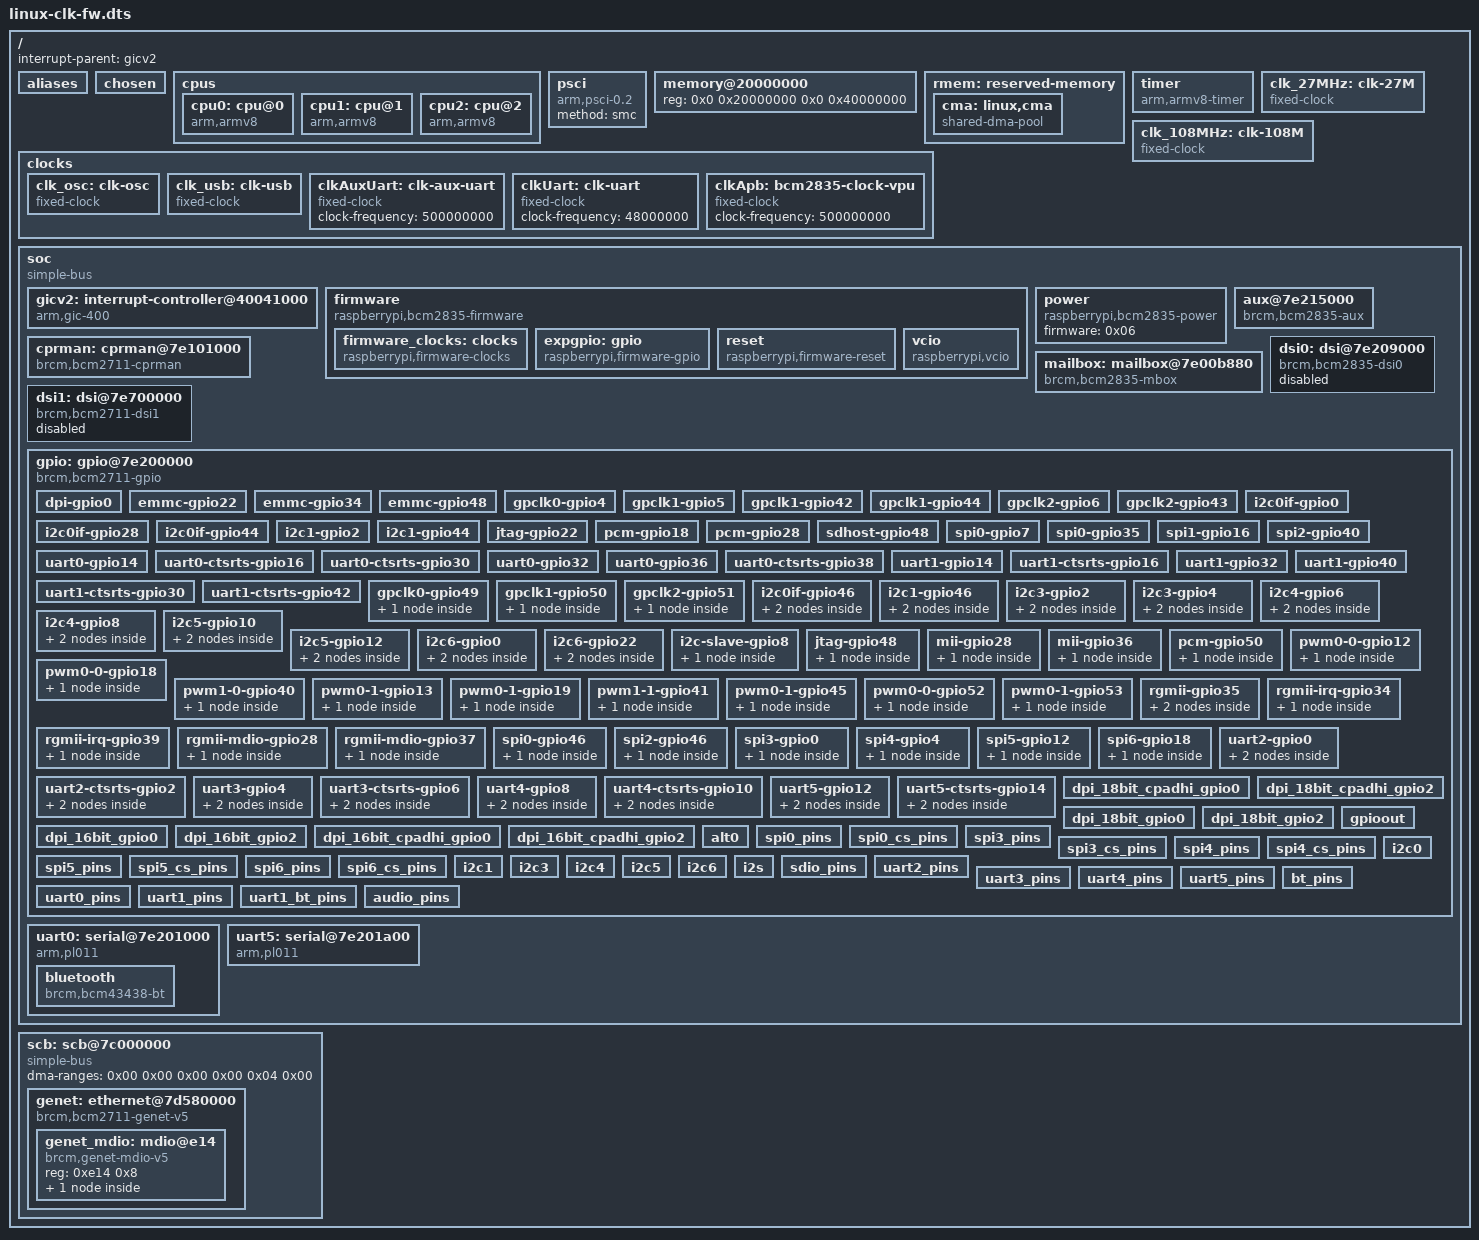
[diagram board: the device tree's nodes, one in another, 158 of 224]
/dts-v1/;

/ {
	#address-cells = <2>;
	#size-cells = <2>;
	interrupt-parent = <&gicv2>;


 aliases: aliases {
	  serial0 = &uart0;
	  serial5 = &uart5;
	  //serial1 = &uart1;
	  ethernet0 = &genet;
	  //clkosc = &clk_osc;
	  //clocks = <&cprman 0>;
	};

 chosen: chosen {
	  stdout-path = "serial0:115200n8";
	  bootargs = "earlycon console=serial0,115200 clk_ignore_unused ip=192.168.42.15 carrier_timeout=0";
	};


 cpus: cpus {
		#size-cells = <0x0>;
		#address-cells = <0x1>;

	cpu0: cpu@0 {
			compatible = "arm,armv8";
			device_type = "cpu";
			enable-method = "psci";
			reg = <0x0>;
		};

	cpu1:	cpu@1 {
			compatible = "arm,armv8";
			device_type = "cpu";
			enable-method = "psci";
			reg = <0x1>;
		};

	cpu2:	cpu@2 {
			compatible = "arm,armv8";
			device_type = "cpu";
			enable-method = "psci";
			reg = <0x2>;
		};

	};

	psci {
		compatible = "arm,psci-0.2";
		method = "smc";
	};

	memory@20000000 {
		reg = <0x0 0x20000000 0x0 0x40000000>;
		device_type = "memory";
	};

 rmem: reserved-memory {
		#address-cells = <0x02>;
		#size-cells = <0x01>;
		ranges;

	cma: linux,cma {
			compatible = "shared-dma-pool";
			size = <0x4000000>;
			reusable;
			linux,cma-default;
		};
	};

	timer {
		compatible = "arm,armv8-timer";
		interrupts = <0x1 0xd 0xf08 0x1 0xe 0xf08 0x1 0xb 0xf08 0x1 0xa 0xf08>;
	};

	clocks {

	clk_osc: clk-osc {
			clock-output-names = "osc";
			#clock-cells = <0x00>;
			clock-frequency = <0x337f980>;
			compatible = "fixed-clock";
			phandle = <0x03>;
		};

	clk_usb:	clk-usb {
			clock-output-names = "otg";
			#clock-cells = <0x00>;
			clock-frequency = <0x1c9c3800>;
			compatible = "fixed-clock";
			phandle = <0x16>;
		};

	    clkAuxUart: clk-aux-uart {
			compatible = "fixed-clock";
			#clock-cells = <0>;
			clock-frequency = <500000000>;
		};
	clkUart: clk-uart {
			compatible = "fixed-clock";
			#clock-cells = <0>;
			clock-frequency = <48000000>;
	  };

	clkApb: bcm2835-clock-vpu {
			compatible = "fixed-clock";
			#clock-cells = <0>;
			clock-frequency = <500000000>;
	  };


	};
 clk_27MHz: clk-27M {
		#clock-cells = <0x00>;
		compatible = "fixed-clock";
		clock-frequency = <0x19bfcc0>;
		clock-output-names = "27MHz-clock";
		phandle = <0x2f>;
	};

 clk_108MHz:	clk-108M {
		#clock-cells = <0x00>;
		compatible = "fixed-clock";
		clock-frequency = <0x66ff300>;
		clock-output-names = "108MHz-clock";
		phandle = <0x2a>;
	};


 soc: soc {
		compatible = "simple-bus";
		#address-cells = <0x01>;
		#size-cells = <0x01>;
		ranges = <0x7e000000 0x00 0xfe000000 0x1800000 0x7c000000 0x00 0xfc000000 0x2000000 0x40000000 0x00 0xff800000 0x800000>;
		dma-ranges = <0xc0000000 0x00 0x00 0x40000000 0x7c000000 0x00 0xfc000000 0x3800000>;
		phandle = <0x5f>;


	gicv2: interrupt-controller@40041000 {
			interrupts = <0x01 0x09 0xf04>;
			compatible = "arm,gic-400";
			#interrupt-cells = <0x03>;
			reg = <0x40041000 0x1000 0x40042000 0x2000 0x40044000 0x2000 0x40046000 0x2000>;
			phandle = <0x01>;
			interrupt-controller;
		};



	firmware:	firmware {
			compatible = "raspberrypi,bcm2835-firmware\0simple-mfd";
			#address-cells = <0x01>;
			#size-cells = <0x01>;
			mboxes = <&mailbox>;
			dma-ranges;
			phandle = <0x06>;

		firmware_clocks:	clocks {
				compatible = "raspberrypi,firmware-clocks";
				#clock-cells = <0x01>;
				phandle = <0x14>;
			};

		expgpio:	gpio {
				compatible = "raspberrypi,firmware-gpio";
				gpio-controller;
				#gpio-cells = <0x02>;
				status = "okay";
				gpio-line-names = "BT_ON\0WL_ON\0PWR_LED_OFF\0GLOBAL_RESET\0VDD_SD_IO_SEL\0CAM_GPIO\0SD_PWR_ON\0SD_OC_N";
				phandle = <0x0b>;
			};

		reset:	reset {
				compatible = "raspberrypi,firmware-reset";
				#reset-cells = <0x01>;
				phandle = <0x3f>;
			};

		vcio:	vcio {
				compatible = "raspberrypi,vcio";
				phandle = <0xdd>;
			};
		};
		
	power:	power {
			compatible = "raspberrypi,bcm2835-power";
			firmware = <0x06>;
			#power-domain-cells = <0x01>;
			phandle = <0x10>;
		};
		
		 aux@7e215000 {
		 	clocks = <&cprman 0x14>;
		 	#clock-cells = <0x01>;
		 	compatible = "brcm,bcm2835-aux";
		 	reg = <0x7e215000 0x08>;
		 	phandle = <0x11>;
		 };
		 
		 
	cprman: cprman@7e101000 {
		 	clocks = <&clk_osc &dsi0 0x00 &dsi0 0x01 &dsi0 0x02 &dsi1 0x00 &dsi1 0x01 &dsi1 0x02>;
		 	#clock-cells = <0x01>;
		 	compatible = "brcm,bcm2711-cprman";
		 	firmware = <0x06>;
		 	reg = <0x7e101000 0x2000>;
		 	phandle = <0x08>;
		 };


	mailbox:	mailbox@7e00b880 {
			compatible = "brcm,bcm2835-mbox";
			reg = <0x7e00b880 0x40>;
			interrupts = <0x00 0x21 0x04>;
			#mbox-cells = <0x00>;
			phandle = <0x35>;
		};

		 
		 
	dsi0:	 dsi@7e209000 {
		 	power-domains = <&power 0x11>;
		 	#address-cells = <0x01>;
		 	clock-output-names = "dsi0_byte\0dsi0_ddr2\0dsi0_ddr";
		 	clock-names = "phy\0escape\0pixel";
		 	interrupts = <0x00 0x64 0x04>;
		 	clocks = <&cprman 0x22 &cprman 0x2f &cprman 0x31>;
		 	#size-cells = <0x00>;
		 	#clock-cells = <0x01>;
		 	compatible = "brcm,bcm2835-dsi0";
		 	status = "disabled";
		 	reg = <0x7e209000 0x78>;
		 	phandle = <0x04>;
		 };
		 
		 
	dsi1:	 dsi@7e700000 {
		 	power-domains = <&power 0x12>;
		 	#address-cells = <0x01>;
		 	clock-output-names = "dsi1_byte\0dsi1_ddr2\0dsi1_ddr";
		 	clock-names = "phy\0escape\0pixel";
		 	interrupts = <0x00 0x6c 0x04>;
		 	clocks = <&cprman 0x23 &cprman 0x30 &cprman 0x32>;
		 	#size-cells = <0x00>;
		 	#clock-cells = <0x01>;
		 	compatible = "brcm,bcm2711-dsi1";
		 	status = "disabled";
		 	reg = <0x7e700000 0x8c>;
		 	phandle = <0x05>;
		 };


	gpio:	gpio@7e200000 {
			compatible = "brcm,bcm2711-gpio";
			reg = <0x7e200000 0xb4>;
			interrupts = <0x00 0x71 0x04 0x00 0x72 0x04>;
			gpio-controller;
			#gpio-cells = <0x02>;
			interrupt-controller;
			#interrupt-cells = <0x02>;
			gpio-ranges = <0x07 0x00 0x00 0x3a>;
			gpio-line-names = "ID_SDA\0ID_SCL\0GPIO2\0GPIO3\0GPIO4\0GPIO5\0GPIO6\0GPIO7\0GPIO8\0GPIO9\0GPIO10\0GPIO11\0GPIO12\0GPIO13\0GPIO14\0GPIO15\0GPIO16\0GPIO17\0GPIO18\0GPIO19\0GPIO20\0GPIO21\0GPIO22\0GPIO23\0GPIO24\0GPIO25\0GPIO26\0GPIO27\0RGMII_MDIO\0RGMIO_MDC\0CTS0\0RTS0\0TXD0\0RXD0\0SD1_CLK\0SD1_CMD\0SD1_DATA0\0SD1_DATA1\0SD1_DATA2\0SD1_DATA3\0PWM0_MISO\0PWM1_MOSI\0STATUS_LED_G_CLK\0SPIFLASH_CE_N\0SDA0\0SCL0\0RGMII_RXCLK\0RGMII_RXCTL\0RGMII_RXD0\0RGMII_RXD1\0RGMII_RXD2\0RGMII_RXD3\0RGMII_TXCLK\0RGMII_TXCTL\0RGMII_TXD0\0RGMII_TXD1\0RGMII_TXD2\0RGMII_TXD3";
			phandle = <0x07>;

			dpi-gpio0 {
				brcm,pins = <0x00 0x01 0x02 0x03 0x04 0x05 0x06 0x07 0x08 0x09 0x0a 0x0b 0x0c 0x0d 0x0e 0x0f 0x10 0x11 0x12 0x13 0x14 0x15 0x16 0x17 0x18 0x19 0x1a 0x1b>;
				brcm,function = <0x06>;
				phandle = <0x64>;
			};

			emmc-gpio22 {
				brcm,pins = <0x16 0x17 0x18 0x19 0x1a 0x1b>;
				brcm,function = <0x07>;
				phandle = <0x65>;
			};

			emmc-gpio34 {
				brcm,pins = <0x22 0x23 0x24 0x25 0x26 0x27>;
				brcm,function = <0x07>;
				brcm,pull = <0x00 0x02 0x02 0x02 0x02 0x02>;
				phandle = <0x66>;
			};

			emmc-gpio48 {
				brcm,pins = <0x30 0x31 0x32 0x33 0x34 0x35>;
				brcm,function = <0x07>;
				phandle = <0x13>;
			};

			gpclk0-gpio4 {
				brcm,pins = <0x04>;
				brcm,function = <0x04>;
				phandle = <0x67>;
			};

			gpclk1-gpio5 {
				brcm,pins = <0x05>;
				brcm,function = <0x04>;
				phandle = <0x68>;
			};

			gpclk1-gpio42 {
				brcm,pins = <0x2a>;
				brcm,function = <0x04>;
				phandle = <0x69>;
			};

			gpclk1-gpio44 {
				brcm,pins = <0x2c>;
				brcm,function = <0x04>;
				phandle = <0x6a>;
			};

			gpclk2-gpio6 {
				brcm,pins = <0x06>;
				brcm,function = <0x04>;
				phandle = <0x6b>;
			};

			gpclk2-gpio43 {
				brcm,pins = <0x2b>;
				brcm,function = <0x04>;
				brcm,pull = <0x00>;
				phandle = <0x6c>;
			};

			i2c0if-gpio0 {
				brcm,pins = <0x00 0x01>;
				brcm,function = <0x04>;
				phandle = <0x33>;
			};

			i2c0if-gpio28 {
				brcm,pins = <0x1c 0x1d>;
				brcm,function = <0x04>;
				phandle = <0x6d>;
			};

			i2c0if-gpio44 {
				brcm,pins = <0x2c 0x2d>;
				brcm,function = <0x05>;
				phandle = <0x34>;
			};

			i2c1-gpio2 {
				brcm,pins = <0x02 0x03>;
				brcm,function = <0x04>;
				phandle = <0x6e>;
			};

			i2c1-gpio44 {
				brcm,pins = <0x2c 0x2d>;
				brcm,function = <0x06>;
				phandle = <0x6f>;
			};

			jtag-gpio22 {
				brcm,pins = <0x16 0x17 0x18 0x19 0x1a 0x1b>;
				brcm,function = <0x03>;
				phandle = <0x70>;
			};

			pcm-gpio18 {
				brcm,pins = <0x12 0x13 0x14 0x15>;
				brcm,function = <0x04>;
				phandle = <0x71>;
			};

			pcm-gpio28 {
				brcm,pins = <0x1c 0x1d 0x1e 0x1f>;
				brcm,function = <0x06>;
				phandle = <0x72>;
			};

			sdhost-gpio48 {
				brcm,pins = <0x30 0x31 0x32 0x33 0x34 0x35>;
				brcm,function = <0x04>;
				phandle = <0x73>;
			};

			spi0-gpio7 {
				brcm,pins = <0x07 0x08 0x09 0x0a 0x0b>;
				brcm,function = <0x04>;
				phandle = <0x74>;
			};

			spi0-gpio35 {
				brcm,pins = <0x23 0x24 0x25 0x26 0x27>;
				brcm,function = <0x04>;
				phandle = <0x75>;
			};

			spi1-gpio16 {
				brcm,pins = <0x10 0x11 0x12 0x13 0x14 0x15>;
				brcm,function = <0x03>;
				phandle = <0x76>;
			};

			spi2-gpio40 {
				brcm,pins = <0x28 0x29 0x2a 0x2b 0x2c 0x2d>;
				brcm,function = <0x03>;
				phandle = <0x77>;
			};

			uart0-gpio14 {
				brcm,pins = <0x0e 0x0f>;
				brcm,function = <0x04>;
				phandle = <0x78>;
			};

			uart0-ctsrts-gpio16 {
				brcm,pins = <0x10 0x11>;
				brcm,function = <0x07>;
				phandle = <0x79>;
			};

			uart0-ctsrts-gpio30 {
				brcm,pins = <0x1e 0x1f>;
				brcm,function = <0x07>;
				brcm,pull = <0x02 0x00>;
				phandle = <0x7a>;
			};

			uart0-gpio32 {
				brcm,pins = <0x20 0x21>;
				brcm,function = <0x07>;
				brcm,pull = <0x00 0x02>;
				phandle = <0x7b>;
			};

			uart0-gpio36 {
				brcm,pins = <0x24 0x25>;
				brcm,function = <0x06>;
				phandle = <0x7c>;
			};

			uart0-ctsrts-gpio38 {
				brcm,pins = <0x26 0x27>;
				brcm,function = <0x06>;
				phandle = <0x7d>;
			};

			uart1-gpio14 {
				brcm,pins = <0x0e 0x0f>;
				brcm,function = <0x02>;
				phandle = <0x7e>;
			};

			uart1-ctsrts-gpio16 {
				brcm,pins = <0x10 0x11>;
				brcm,function = <0x02>;
				phandle = <0x7f>;
			};

			uart1-gpio32 {
				brcm,pins = <0x20 0x21>;
				brcm,function = <0x02>;
				phandle = <0x80>;
			};

			uart1-ctsrts-gpio30 {
				brcm,pins = <0x1e 0x1f>;
				brcm,function = <0x02>;
				phandle = <0x81>;
			};

			uart1-gpio40 {
				brcm,pins = <0x28 0x29>;
				brcm,function = <0x02>;
				phandle = <0x82>;
			};

			uart1-ctsrts-gpio42 {
				brcm,pins = <0x2a 0x2b>;
				brcm,function = <0x02>;
				phandle = <0x83>;
			};

			gpclk0-gpio49 {
				phandle = <0x84>;

				pin-gpclk {
					pins = "gpio49";
					function = "alt1";
					bias-disable;
				};
			};

			gpclk1-gpio50 {
				phandle = <0x85>;

				pin-gpclk {
					pins = "gpio50";
					function = "alt1";
					bias-disable;
				};
			};

			gpclk2-gpio51 {
				phandle = <0x86>;

				pin-gpclk {
					pins = "gpio51";
					function = "alt1";
					bias-disable;
				};
			};

			i2c0if-gpio46 {
				phandle = <0x87>;

				pin-sda {
					function = "alt0";
					pins = "gpio46";
					bias-pull-up;
				};

				pin-scl {
					function = "alt0";
					pins = "gpio47";
					bias-disable;
				};
			};

			i2c1-gpio46 {
				phandle = <0x88>;

				pin-sda {
					function = "alt1";
					pins = "gpio46";
					bias-pull-up;
				};

				pin-scl {
					function = "alt1";
					pins = "gpio47";
					bias-disable;
				};
			};

			i2c3-gpio2 {
				phandle = <0x89>;

				pin-sda {
					function = "alt5";
					pins = "gpio2";
					bias-pull-up;
				};

				pin-scl {
					function = "alt5";
					pins = "gpio3";
					bias-disable;
				};
			};

			i2c3-gpio4 {
				phandle = <0x8a>;

				pin-sda {
					function = "alt5";
					pins = "gpio4";
					bias-pull-up;
				};

				pin-scl {
					function = "alt5";
					pins = "gpio5";
					bias-disable;
				};
			};

			i2c4-gpio6 {
				phandle = <0x8b>;

				pin-sda {
					function = "alt5";
					pins = "gpio6";
					bias-pull-up;
				};

				pin-scl {
					function = "alt5";
					pins = "gpio7";
					bias-disable;
				};
			};

			i2c4-gpio8 {
				phandle = <0x8c>;

				pin-sda {
					function = "alt5";
					pins = "gpio8";
					bias-pull-up;
				};

				pin-scl {
					function = "alt5";
					pins = "gpio9";
					bias-disable;
				};
			};

			i2c5-gpio10 {
				phandle = <0x8d>;

				pin-sda {
					function = "alt5";
					pins = "gpio10";
					bias-pull-up;
				};

				pin-scl {
					function = "alt5";
					pins = "gpio11";
					bias-disable;
				};
			};

			i2c5-gpio12 {
				phandle = <0x8e>;

				pin-sda {
					function = "alt5";
					pins = "gpio12";
					bias-pull-up;
				};

				pin-scl {
					function = "alt5";
					pins = "gpio13";
					bias-disable;
				};
			};

			i2c6-gpio0 {
				phandle = <0x8f>;

				pin-sda {
					function = "alt5";
					pins = "gpio0";
					bias-pull-up;
				};

				pin-scl {
					function = "alt5";
					pins = "gpio1";
					bias-disable;
				};
			};

			i2c6-gpio22 {
				phandle = <0x90>;

				pin-sda {
					function = "alt5";
					pins = "gpio22";
					bias-pull-up;
				};

				pin-scl {
					function = "alt5";
					pins = "gpio23";
					bias-disable;
				};
			};

			i2c-slave-gpio8 {
				phandle = <0x91>;

				pins-i2c-slave {
					pins = "gpio8\0gpio9\0gpio10\0gpio11";
					function = "alt3";
				};
			};

			jtag-gpio48 {
				phandle = <0x92>;

				pins-jtag {
					pins = "gpio48\0gpio49\0gpio50\0gpio51\0gpio52\0gpio53";
					function = "alt4";
				};
			};

			mii-gpio28 {
				phandle = <0x93>;

				pins-mii {
					pins = "gpio28\0gpio29\0gpio30\0gpio31";
					function = "alt4";
				};
			};

			mii-gpio36 {
				phandle = <0x94>;

				pins-mii {
					pins = "gpio36\0gpio37\0gpio38\0gpio39";
					function = "alt5";
				};
			};

			pcm-gpio50 {
				phandle = <0x95>;

				pins-pcm {
					pins = "gpio50\0gpio51\0gpio52\0gpio53";
					function = "alt2";
				};
			};

			pwm0-0-gpio12 {
				phandle = <0x96>;

				pin-pwm {
					pins = "gpio12";
					function = "alt0";
					bias-disable;
				};
			};

			pwm0-0-gpio18 {
				phandle = <0x97>;

				pin-pwm {
					pins = "gpio18";
					function = "alt5";
					bias-disable;
				};
			};

			pwm1-0-gpio40 {
				phandle = <0x28>;

				pin-pwm {
					pins = "gpio40";
					function = "alt0";
					bias-disable;
				};
			};

			pwm0-1-gpio13 {
				phandle = <0x98>;

				pin-pwm {
					pins = "gpio13";
					function = "alt0";
					bias-disable;
				};
			};

			pwm0-1-gpio19 {
				phandle = <0x99>;

				pin-pwm {
					pins = "gpio19";
					function = "alt5";
					bias-disable;
				};
			};

			pwm1-1-gpio41 {
				phandle = <0x29>;

				pin-pwm {
					pins = "gpio41";
					function = "alt0";
					bias-disable;
				};
			};

			pwm0-1-gpio45 {
				phandle = <0x9a>;

				pin-pwm {
					pins = "gpio45";
					function = "alt0";
					bias-disable;
				};
			};

			pwm0-0-gpio52 {
				phandle = <0x9b>;

				pin-pwm {
					pins = "gpio52";
					function = "alt1";
					bias-disable;
				};
			};

			pwm0-1-gpio53 {
				phandle = <0x9c>;

				pin-pwm {
					pins = "gpio53";
					function = "alt1";
					bias-disable;
				};
			};

			rgmii-gpio35 {
				phandle = <0x9d>;

				pin-start-stop {
					pins = "gpio35";
					function = "alt4";
				};

				pin-rx-ok {
					pins = "gpio36";
					function = "alt4";
				};
			};

			rgmii-irq-gpio34 {
				phandle = <0x9e>;

				pin-irq {
					pins = "gpio34";
					function = "alt5";
				};
			};

			rgmii-irq-gpio39 {
				phandle = <0x9f>;

				pin-irq {
					pins = "gpio39";
					function = "alt4";
				};
			};

			rgmii-mdio-gpio28 {
				phandle = <0xa0>;

				pins-mdio {
					pins = "gpio28\0gpio29";
					function = "alt5";
				};
			};

			rgmii-mdio-gpio37 {
				phandle = <0xa1>;

				pins-mdio {
					pins = "gpio37\0gpio38";
					function = "alt4";
				};
			};

			spi0-gpio46 {
				phandle = <0xa2>;

				pins-spi {
					pins = "gpio46\0gpio47\0gpio48\0gpio49";
					function = "alt2";
				};
			};

			spi2-gpio46 {
				phandle = <0xa3>;

				pins-spi {
					pins = "gpio46\0gpio47\0gpio48\0gpio49\0gpio50";
					function = "alt5";
				};
			};

			spi3-gpio0 {
				phandle = <0xa4>;

				pins-spi {
					pins = "gpio0\0gpio1\0gpio2\0gpio3";
					function = "alt3";
				};
			};

			spi4-gpio4 {
				phandle = <0xa5>;

				pins-spi {
					pins = "gpio4\0gpio5\0gpio6\0gpio7";
					function = "alt3";
				};
			};

			spi5-gpio12 {
				phandle = <0xa6>;

				pins-spi {
					pins = "gpio12\0gpio13\0gpio14\0gpio15";
					function = "alt3";
				};
			};

			spi6-gpio18 {
				phandle = <0xa7>;

				pins-spi {
					pins = "gpio18\0gpio19\0gpio20\0gpio21";
					function = "alt3";
				};
			};

			uart2-gpio0 {
				phandle = <0xa8>;

				pin-tx {
					pins = "gpio0";
					function = "alt4";
					bias-disable;
				};

				pin-rx {
					pins = "gpio1";
					function = "alt4";
					bias-pull-up;
				};
			};

			uart2-ctsrts-gpio2 {
				phandle = <0xa9>;

				pin-cts {
					pins = "gpio2";
					function = "alt4";
					bias-pull-up;
				};

				pin-rts {
					pins = "gpio3";
					function = "alt4";
					bias-disable;
				};
			};

			uart3-gpio4 {
				phandle = <0xaa>;

				pin-tx {
					pins = "gpio4";
					function = "alt4";
					bias-disable;
				};

				pin-rx {
					pins = "gpio5";
					function = "alt4";
					bias-pull-up;
				};
			};

			uart3-ctsrts-gpio6 {
				phandle = <0xab>;

				pin-cts {
					pins = "gpio6";
					function = "alt4";
					bias-pull-up;
				};

				pin-rts {
					pins = "gpio7";
					function = "alt4";
					bias-disable;
				};
			};

			uart4-gpio8 {
				phandle = <0xac>;

				pin-tx {
					pins = "gpio8";
					function = "alt4";
					bias-disable;
				};

				pin-rx {
					pins = "gpio9";
					function = "alt4";
					bias-pull-up;
				};
			};

			uart4-ctsrts-gpio10 {
				phandle = <0xad>;

				pin-cts {
					pins = "gpio10";
					function = "alt4";
					bias-pull-up;
				};

				pin-rts {
					pins = "gpio11";
					function = "alt4";
					bias-disable;
				};
			};

			uart5-gpio12 {
				phandle = <0xae>;

				pin-tx {
					pins = "gpio12";
					function = "alt4";
					bias-disable;
				};

				pin-rx {
					pins = "gpio13";
					function = "alt4";
					bias-pull-up;
				};
			};

			uart5-ctsrts-gpio14 {
				phandle = <0xaf>;

				pin-cts {
					pins = "gpio14";
					function = "alt4";
					bias-pull-up;
				};

				pin-rts {
					pins = "gpio15";
					function = "alt4";
					bias-disable;
				};
			};

			dpi_18bit_cpadhi_gpio0 {
				brcm,pins = <0x00 0x01 0x02 0x03 0x04 0x05 0x06 0x07 0x08 0x09 0x0c 0x0d 0x0e 0x0f 0x10 0x11 0x14 0x15 0x16 0x17 0x18 0x19>;
				brcm,function = <0x06>;
				brcm,pull = <0x00>;
				phandle = <0xb0>;
			};

			dpi_18bit_cpadhi_gpio2 {
				brcm,pins = <0x02 0x03 0x04 0x05 0x06 0x07 0x08 0x09 0x0c 0x0d 0x0e 0x0f 0x10 0x11 0x14 0x15 0x16 0x17 0x18 0x19>;
				brcm,function = <0x06>;
				phandle = <0xb1>;
			};

			dpi_18bit_gpio0 {
				brcm,pins = <0x00 0x01 0x02 0x03 0x04 0x05 0x06 0x07 0x08 0x09 0x0a 0x0b 0x0c 0x0d 0x0e 0x0f 0x10 0x11 0x12 0x13 0x14 0x15>;
				brcm,function = <0x06>;
				phandle = <0xb2>;
			};

			dpi_18bit_gpio2 {
				brcm,pins = <0x02 0x03 0x04 0x05 0x06 0x07 0x08 0x09 0x0a 0x0b 0x0c 0x0d 0x0e 0x0f 0x10 0x11 0x12 0x13 0x14 0x15>;
				brcm,function = <0x06>;
				phandle = <0xb3>;
			};

			dpi_16bit_gpio0 {
				brcm,pins = <0x00 0x01 0x02 0x03 0x04 0x05 0x06 0x07 0x08 0x09 0x0a 0x0b 0x0c 0x0d 0x0e 0x0f 0x10 0x11 0x12 0x13>;
				brcm,function = <0x06>;
				phandle = <0xb4>;
			};

			dpi_16bit_gpio2 {
				brcm,pins = <0x02 0x03 0x04 0x05 0x06 0x07 0x08 0x09 0x0a 0x0b 0x0c 0x0d 0x0e 0x0f 0x10 0x11 0x12 0x13>;
				brcm,function = <0x06>;
				phandle = <0xb5>;
			};

			dpi_16bit_cpadhi_gpio0 {
				brcm,pins = <0x00 0x01 0x02 0x03 0x04 0x05 0x06 0x07 0x08 0x0c 0x0d 0x0e 0x0f 0x10 0x11 0x14 0x15 0x16 0x17 0x18>;
				brcm,function = <0x06>;
				phandle = <0xb6>;
			};

			dpi_16bit_cpadhi_gpio2 {
				brcm,pins = <0x02 0x03 0x04 0x05 0x06 0x07 0x08 0x0c 0x0d 0x0e 0x0f 0x10 0x11 0x14 0x15 0x16 0x17 0x18>;
				brcm,function = <0x06>;
				phandle = <0xb7>;
			};

			gpioout {
				brcm,pins = <0x06>;
				brcm,function = <0x01>;
				phandle = <0xb8>;
			};

			alt0 {
				brcm,pins = <0x04 0x05 0x07 0x08 0x09 0x0a 0x0b>;
				brcm,function = <0x04>;
				phandle = <0xb9>;
			};

			spi0_pins {
				brcm,pins = <0x09 0x0a 0x0b>;
				brcm,function = <0x04>;
				phandle = <0x0e>;
			};

			spi0_cs_pins {
				brcm,pins = <0x08 0x07>;
				brcm,function = <0x01>;
				phandle = <0x0f>;
			};

			spi3_pins {
				brcm,pins = <0x01 0x02 0x03>;
				brcm,function = <0x07>;
				phandle = <0x1c>;
			};

			spi3_cs_pins {
				brcm,pins = <0x00 0x18>;
				brcm,function = <0x01>;
				phandle = <0x1d>;
			};

			spi4_pins {
				brcm,pins = <0x05 0x06 0x07>;
				brcm,function = <0x07>;
				phandle = <0x1e>;
			};

			spi4_cs_pins {
				brcm,pins = <0x04 0x19>;
				brcm,function = <0x01>;
				phandle = <0x1f>;
			};

			spi5_pins {
				brcm,pins = <0x0d 0x0e 0x0f>;
				brcm,function = <0x07>;
				phandle = <0x20>;
			};

			spi5_cs_pins {
				brcm,pins = <0x0c 0x1a>;
				brcm,function = <0x01>;
				phandle = <0x21>;
			};

			spi6_pins {
				brcm,pins = <0x13 0x14 0x15>;
				brcm,function = <0x07>;
				phandle = <0x22>;
			};

			spi6_cs_pins {
				brcm,pins = <0x12 0x1b>;
				brcm,function = <0x01>;
				phandle = <0x23>;
			};

			i2c0 {
				brcm,pins = <0x00 0x01>;
				brcm,function = <0x04>;
				brcm,pull = <0x02>;
				phandle = <0xba>;
			};

			i2c1 {
				brcm,pins = <0x02 0x03>;
				brcm,function = <0x04>;
				brcm,pull = <0x02>;
				phandle = <0x15>;
			};

			i2c3 {
				brcm,pins = <0x04 0x05>;
				brcm,function = <0x02>;
				brcm,pull = <0x02>;
				phandle = <0x24>;
			};

			i2c4 {
				brcm,pins = <0x08 0x09>;
				brcm,function = <0x02>;
				brcm,pull = <0x02>;
				phandle = <0x25>;
			};

			i2c5 {
				brcm,pins = <0x0c 0x0d>;
				brcm,function = <0x02>;
				brcm,pull = <0x02>;
				phandle = <0x26>;
			};

			i2c6 {
				brcm,pins = <0x16 0x17>;
				brcm,function = <0x02>;
				brcm,pull = <0x02>;
				phandle = <0x27>;
			};

			i2s {
				brcm,pins = <0x12 0x13 0x14 0x15>;
				brcm,function = <0x04>;
				phandle = <0x0d>;
			};

			sdio_pins {
				brcm,pins = <0x22 0x23 0x24 0x25 0x26 0x27>;
				brcm,function = <0x07>;
				brcm,pull = <0x00 0x02 0x02 0x02 0x02 0x02>;
				phandle = <0x31>;
			};

			uart2_pins {
				brcm,pins = <0x00 0x01>;
				brcm,function = <0x03>;
				brcm,pull = <0x00 0x02>;
				phandle = <0x18>;
			};

			uart3_pins {
				brcm,pins = <0x04 0x05>;
				brcm,function = <0x03>;
				brcm,pull = <0x00 0x02>;
				phandle = <0x19>;
			};

			uart4_pins {
				brcm,pins = <0x08 0x09>;
				brcm,function = <0x03>;
				brcm,pull = <0x00 0x02>;
				phandle = <0x1a>;
			};

		uart5_pins:	uart5_pins {
				brcm,pins = <0x0c 0x0d>;
				brcm,function = <0x03>;
				brcm,pull = <0x00 0x02>;
				phandle = <0x1b>;
			};

			bt_pins {
				brcm,pins = "-";
				brcm,function = <0x00>;
				brcm,pull = <0x02>;
				phandle = <0x0a>;
			};

		uart0_pins: uart0_pins {
			  brcm,pins = <0x20 0x21>;
			  brcm,function = <0x02>;
			  brcm,pull = <0x00 0x02>;
			  phandle = <0x09>;
			};

			uart1_pins {
				brcm,pins;
				brcm,function;
				brcm,pull;
				phandle = <0x12>;
			};

			uart1_bt_pins {
				brcm,pins = <0x20 0x21 0x1e 0x1f>;
				brcm,function = <0x02>;
				brcm,pull = <0x00 0x02 0x02 0x00>;
				phandle = <0xbb>;
			};

			audio_pins {
				brcm,pins = <0x28 0x29>;
				brcm,function = <0x04>;
				brcm,pull = <0x00>;
				phandle = <0x36>;
			};
		};


		 //		pwm@7e20c000 {
		 //			compatible = "brcm,bcm2835-pwm";
		 //			reg = <0x7e20c000 0x28>;
		 //			clocks = <&cprman 0x1e>;
		 //			assigned-clocks = <&cprman 0x1e>;
		 //			assigned-clock-rates = <0x2faf080>;
		 //			#pwm-cells = <0x03>;
		 //			status = "disabled";
		 //			phandle = <0xc1>;
		 //		};
		 //
		 //		pwm@7e20c800 {
		 //			compatible = "brcm,bcm2835-pwm";
		 //			reg = <0x7e20c800 0x28>;
		 //			clocks = <&cprman 0x1e>;
		 //			assigned-clocks = <&cprman 0x1e>;
		 //			assigned-clock-rates = <0x2faf080>;
		 //			#pwm-cells = <0x03>;
		 //			status = "disabled";
		 //			pinctrl-names = "default";
		 //			pinctrl-0 = <0x28 0x29>;
		 //			phandle = <0xd5>;
		 //		};

		//		u0_pins: uart0_pins {
		//			  //brcm,pins = <0x20 0x21>;
		//				brcm,pins = <0x0e 0x0f>;
		//				brcm,function = <0x04>;
		//				brcm,pull = <0x00 0x02>;
		//				phandle = <0x09>;
		//			};


	uart0: serial@7e201000 {
			compatible = "arm,pl011\0arm,primecell";
			reg = <0x7e201000 0x200>;
			interrupts = <0x00 0x79 0x04>;
			//clocks = <0x08 0x13 0x08 0x14>;
			clocks = <&cprman 0x13 &cprman 0x14>;
			clock-names = "uartclk\0apb_pclk";
			arm,primecell-periphid = <0x241011>;
			status = "okay";
			cts-event-workaround;
			pinctrl-names = "default";
			pinctrl-0 = <0x09 0x0a>;
			uart-has-rtscts;
			skip-init;
			phandle = <0x43>;

			bluetooth {
				compatible = "brcm,bcm43438-bt";
				max-speed = <0x2dc6c0>;
				shutdown-gpios = <&expgpio 0x00 0x00>;
				local-bd-address = [00 00 00 00 00 00];
				fallback-bd-address;
				status = "okay";
				phandle = <0x41>;
			};
		};

		//u5_pins: uart5_pins {
		//			brcm,pins = <0x0c 0x0d>;
		//			brcm,function = <0x03>;
		//			brcm,pull = <0x00 0x02>;
		//			phandle = <0x1b>;
		//		};
		//
		uart5: serial@7e201a00 {
			compatible = "arm,pl011\0arm,primecell";
			reg = <0x7e201a00 0x200>;
			interrupts = <0x00 0x79 0x04>;
			//clocks = <0x08 0x13 0x08 0x14>;
			clocks = <&cprman 0x13 &cprman 0x14>;
			clock-names = "uartclk\0apb_pclk";
			arm,primecell-periphid = <0x241011>;
			//status = "disabled";
			status = "okay";
			pinctrl-0 = <&uart5_pins>;
			pinctrl-names = "default";
			phandle = <0xc7>;
		 };


		//uart1: serial@7e215040 {
		//	  compatible = "brcm,bcm2835-aux-uart";
		//	  reg = <0x7e215040 0x40>;
		//	  interrupts = <0x00 0x5d 0x04>;
		//	  //clocks = <&clkAuxUart>;
		//	  clocks = <0x11 0x00>;
		//	  status = "okay";
		//	};

	};



 scb: scb@7c000000 {
		compatible = "simple-bus";
		#address-cells = <0x02>;
		#size-cells = < 0x02 >;
		dma-ranges = < 0x00 0x00 0x00 0x00 0x04 0x00 >;
		ranges = < 0x00 0x7c000000 0x00 0xfc000000 0x00 0x3800000 0x00 0x40000000 0x00 0xff800000 0x00 0x800000 0x06 0x00 0x06 0x00 0x00 0x40000000 0x00 0x00 0x00 0x00 0x00 0xfc000000 >;

		genet: ethernet@7d580000 {
			local-mac-address = [dc a6 32 a3 9c 57];
			compatible = "brcm,bcm2711-genet-v5", "brcm,genet-v5";
			reg = < 0x00 0x7d580000 0x00 0x10000 >;
			#address-cells = <0x1>;
			#size-cells = <0x1>;
			interrupts = <0 157 4>,
						<0 158 4>;
			status = "okay";

			phy-handle = <&phy1>;
			phy-mode = "rgmii-rxid";

			genet_mdio: mdio@e14 {
				compatible = "brcm,genet-mdio-v5";
				reg = <0xe14 0x8>;
				reg-names = "mdio";
				#address-cells = <0x0>;
				#size-cells = <0x1>;

				phy1: ethernet-phy@1 {
					reg = <0x01>;
					led-modes = < 0x00 0x08 >;
				};
			};
		};
	};

	//    bao-ipc@f0000000 {
	//        compatible = "bao,ipcshmem";
	//        reg = <0x0 0xf0000000 0x0 0x00010000>;
	//		read-channel = <0x0 0x2000>;
	//		write-channel = <0x2000 0x2000>;
	//        interrupts = <0 52 1>;
	//		id = <0>;
	//    };

};
